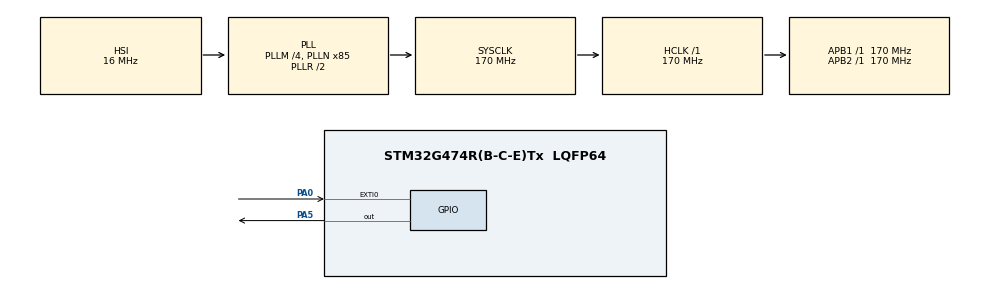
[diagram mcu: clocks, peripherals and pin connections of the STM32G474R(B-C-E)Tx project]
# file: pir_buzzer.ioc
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Mcu.Family=STM32G4
Mcu.Name=STM32G474R(B-C-E)Tx
Mcu.Package=LQFP64
NVIC.EXTI0_IRQn=true\:0\:0\:false\:false\:true\:true\:true\:true
NVIC.PriorityGroup=NVIC_PRIORITYGROUP_4
PA0.GPIO_ModeDefaultEXTI=GPIO_MODE_IT_RISING_FALLING
PA0.Signal=GPXTI0
PA5.PinState=GPIO_PIN_RESET
PA5.Signal=GPIO_Output
ProjectManager.HeapSize=0x200
ProjectManager.StackSize=0x400
ProjectManager.TargetToolchain=STM32CubeIDE
RCC.ADC12Freq_Value=170000000
RCC.ADC345Freq_Value=170000000
RCC.AHBFreq_Value=170000000
RCC.APB1Freq_Value=170000000
RCC.APB1TimFreq_Value=170000000
RCC.APB2Freq_Value=170000000
RCC.APB2TimFreq_Value=170000000
RCC.CortexFreq_Value=170000000
RCC.EXTERNAL_CLOCK_VALUE=12288000
RCC.HCLKFreq_Value=170000000
RCC.HSE_VALUE=24000000
RCC.HSI48_VALUE=48000000
RCC.HSI_VALUE=16000000
RCC.LSE_VALUE=32768
RCC.PLLM=RCC_PLLM_DIV4
RCC.PLLN=85
RCC.RTCClockSelection=RCC_RTCCLKSOURCE_LSE
RCC.SYSCLKFreq_VALUE=170000000
RCC.SYSCLKSource=RCC_SYSCLKSOURCE_PLLCLK
RCC.USBFreq_Value=170000000
RCC.VCOOutputFreq_Value=340000000
board=NUCLEO-G474RE

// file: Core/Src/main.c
/* USER CODE BEGIN Header */
/**
  ******************************************************************************
  * @file           : main.c
  * @brief          : Main program body
  ******************************************************************************
  * @attention
  *
  * Copyright (c) 2024 STMicroelectronics.
  * All rights reserved.
  *
  * This software is licensed under terms that can be found in the LICENSE file
  * in the root directory of this software component.
  * If no LICENSE file comes with this software, it is provided AS-IS.
  *
  ******************************************************************************
  */
/* USER CODE END Header */
#include "main.h"

/* USER CODE BEGIN PD */
#define PIR_SENSOR_PIN GPIO_PIN_0
#define PIR_SENSOR_PORT GPIOA
#define LED_PIN GPIO_PIN_5
#define LED_PORT GPIOA
/* USER CODE END PD */

uint8_t pirStatus = 0;

void SystemClock_Config(void);
static void MX_GPIO_Init(void);

/* USER CODE BEGIN 0 */
void HAL_GPIO_EXTI_Callback(uint16_t GPIO_Pin) {
    if (GPIO_Pin == PIR_SENSOR_PIN) {
        pirStatus = HAL_GPIO_ReadPin(PIR_SENSOR_PORT, PIR_SENSOR_PIN);
    }
}
/* USER CODE END 0 */

int main(void)
{

  /* MCU Configuration--------------------------------------------------------*/

  /* Reset of all peripherals, Initializes the Flash interface and the Systick. */
  HAL_Init();

  /* Configure the system clock */
  SystemClock_Config();

  /* Initialize all configured peripherals */
  MX_GPIO_Init();

  /* Infinite loop */
  /* USER CODE BEGIN WHILE */
  while (1) {
    if (pirStatus) {
        HAL_GPIO_WritePin(LED_PORT, LED_PIN, GPIO_PIN_SET); // Turn on LED
        HAL_Delay(1000);
        HAL_GPIO_WritePin(LED_PORT, LED_PIN, GPIO_PIN_RESET); // Turn off LED
        pirStatus = 0;
    }
  }
    /* USER CODE END WHILE */

}

void SystemClock_Config(void)
{
  RCC_OscInitTypeDef RCC_OscInitStruct = {0};
  RCC_ClkInitTypeDef RCC_ClkInitStruct = {0};

  /** Configure the main internal regulator output voltage
  */
  HAL_PWREx_ControlVoltageScaling(PWR_REGULATOR_VOLTAGE_SCALE1_BOOST);

  /** Initializes the RCC Oscillators according to the specified parameters
  * in the RCC_OscInitTypeDef structure.
  */
  RCC_OscInitStruct.OscillatorType = RCC_OSCILLATORTYPE_HSI;
  RCC_OscInitStruct.HSIState = RCC_HSI_ON;
  RCC_OscInitStruct.HSICalibrationValue = RCC_HSICALIBRATION_DEFAULT;
  RCC_OscInitStruct.PLL.PLLState = RCC_PLL_ON;
  RCC_OscInitStruct.PLL.PLLSource = RCC_PLLSOURCE_HSI;
  RCC_OscInitStruct.PLL.PLLM = RCC_PLLM_DIV4;
  RCC_OscInitStruct.PLL.PLLN = 85;
  RCC_OscInitStruct.PLL.PLLP = RCC_PLLP_DIV2;
  RCC_OscInitStruct.PLL.PLLQ = RCC_PLLQ_DIV2;
  RCC_OscInitStruct.PLL.PLLR = RCC_PLLR_DIV2;
  if (HAL_RCC_OscConfig(&RCC_OscInitStruct) != HAL_OK)
  {
    Error_Handler();
  }

  /** Initializes the CPU, AHB and APB buses clocks
  */
  RCC_ClkInitStruct.ClockType = RCC_CLOCKTYPE_HCLK|RCC_CLOCKTYPE_SYSCLK
                              |RCC_CLOCKTYPE_PCLK1|RCC_CLOCKTYPE_PCLK2;
  RCC_ClkInitStruct.SYSCLKSource = RCC_SYSCLKSOURCE_PLLCLK;
  RCC_ClkInitStruct.AHBCLKDivider = RCC_SYSCLK_DIV1;
  RCC_ClkInitStruct.APB1CLKDivider = RCC_HCLK_DIV1;
  RCC_ClkInitStruct.APB2CLKDivider = RCC_HCLK_DIV1;

  if (HAL_RCC_ClockConfig(&RCC_ClkInitStruct, FLASH_LATENCY_4) != HAL_OK)
  {
    Error_Handler();
  }
}

static void MX_GPIO_Init(void)
{
  GPIO_InitTypeDef GPIO_InitStruct = {0};

  /* GPIO Ports Clock Enable */
  __HAL_RCC_GPIOC_CLK_ENABLE();
  __HAL_RCC_GPIOF_CLK_ENABLE();
  __HAL_RCC_GPIOA_CLK_ENABLE();
  __HAL_RCC_GPIOB_CLK_ENABLE();

  /*Configure GPIO pin Output Level */
  HAL_GPIO_WritePin(LED_PORT, LED_PIN, GPIO_PIN_RESET);

  /*Configure GPIO pin : PA0 */
  GPIO_InitStruct.Pin = PIR_SENSOR_PIN;
  GPIO_InitStruct.Mode = GPIO_MODE_IT_RISING_FALLING;
  GPIO_InitStruct.Pull = GPIO_NOPULL;
  HAL_GPIO_Init(PIR_SENSOR_PORT, &GPIO_InitStruct);

  /*Configure GPIO pins : LPUART1_TX_Pin LPUART1_RX_Pin */
  // GPIO_InitStruct.Pin = LPUART1_TX_Pin|LPUART1_RX_Pin;
  GPIO_InitStruct.Mode = GPIO_MODE_AF_PP;
  GPIO_InitStruct.Pull = GPIO_NOPULL;
  GPIO_InitStruct.Speed = GPIO_SPEED_FREQ_LOW;
  GPIO_InitStruct.Alternate = GPIO_AF12_LPUART1;
  HAL_GPIO_Init(GPIOA, &GPIO_InitStruct);

  /*Configure GPIO pin : LD2_Pin */
  GPIO_InitStruct.Pin = LED_PIN;
  GPIO_InitStruct.Mode = GPIO_MODE_OUTPUT_PP;
  GPIO_InitStruct.Pull = GPIO_NOPULL;
  GPIO_InitStruct.Speed = GPIO_SPEED_FREQ_LOW;
  HAL_GPIO_Init(LED_PORT, &GPIO_InitStruct);

}

void Error_Handler(void)
{
  __disable_irq();
  while (1)
  {
  }
}
